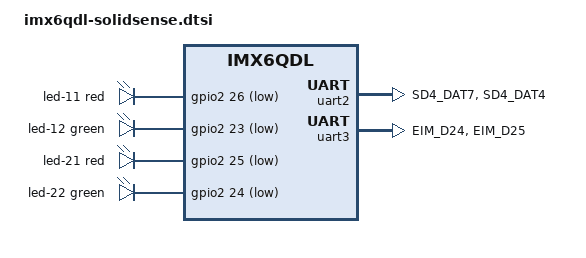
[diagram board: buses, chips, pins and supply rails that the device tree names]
#include <dt-bindings/leds/common.h>
/ {
	leds {
		compatible = "gpio-leds";
		pinctrl-names = "default";
		pinctrl-0 = <&pinctrl_solidsense_leds>;
		led-11 {
			color = <LED_COLOR_ID_RED>;
			function = LED_FUNCTION_INDICATOR;
			function-enumerator = <0>;
			gpios = <&gpio2 26 GPIO_ACTIVE_LOW>;
		};
		led-12 {
			color = <LED_COLOR_ID_GREEN>;
			function = LED_FUNCTION_INDICATOR;
			function-enumerator = <0>;
			gpios = <&gpio2 23 GPIO_ACTIVE_LOW>;
		};
		led-21 {
			color = <LED_COLOR_ID_RED>;
			function = LED_FUNCTION_INDICATOR;
			function-enumerator = <1>;
			gpios = <&gpio2 25 GPIO_ACTIVE_LOW>;
		};
		led-22 {
			color = <LED_COLOR_ID_GREEN>;
			function = LED_FUNCTION_INDICATOR;
			function-enumerator = <1>;
			gpios = <&gpio2 24 GPIO_ACTIVE_LOW>;
		};
	};
};
&audio {
	status = "disabled";
};
&ecspi2 {
	status = "disabled";
};
&i2c3 {
	status = "disabled";
};
&iomuxc {
	pinctrl-0 = <&pinctrl_hog>, <&pinctrl_solidsense_hog>;
	solidsense {
		pinctrl_solidsense_hog: solidsense-hog {
			fsl,pins = <
				MX6QDL_PAD_GPIO_9__GPIO1_IO09 0x400130b1
				MX6QDL_PAD_DISP0_DAT8__GPIO4_IO29 0x400130b1
				MX6QDL_PAD_EIM_D17__GPIO3_IO17 0x400130b1
				MX6QDL_PAD_EIM_D18__GPIO3_IO18 0x400130b1
			>;
		};
		pinctrl_solidsense_leds: solidsense-leds {
			fsl,pins = <
				MX6QDL_PAD_EIM_RW__GPIO2_IO26 0x400130b1
				MX6QDL_PAD_EIM_CS0__GPIO2_IO23 0x400130b1
				MX6QDL_PAD_EIM_OE__GPIO2_IO25 0x400130b1
				MX6QDL_PAD_EIM_CS1__GPIO2_IO24 0x400130b1
			>;
		};
		pinctrl_solidsense_uart2: solidsense-uart2 {
			fsl,pins = <
				MX6QDL_PAD_SD4_DAT7__UART2_TX_DATA	0x1b0b1
				MX6QDL_PAD_SD4_DAT4__UART2_RX_DATA	0x1b0b1
			>;
		};
		pinctrl_solidsense_uart3: solidsense-uart3 {
			fsl,pins = <
				MX6QDL_PAD_EIM_D24__UART3_TX_DATA	0x1b0b1
				MX6QDL_PAD_EIM_D25__UART3_RX_DATA	0x1b0b1
			>;
		};
	};
};
&pwm1 {
	status = "disabled";
};
&sgtl5000 {
	status = "disabled";
};
&uart2 {
	pinctrl-names = "default";
	pinctrl-0 = <&pinctrl_solidsense_uart2>;
	status = "okay";
};
&uart3 {
	pinctrl-names = "default";
	pinctrl-0 = <&pinctrl_solidsense_uart3>;
	status = "okay";
};
